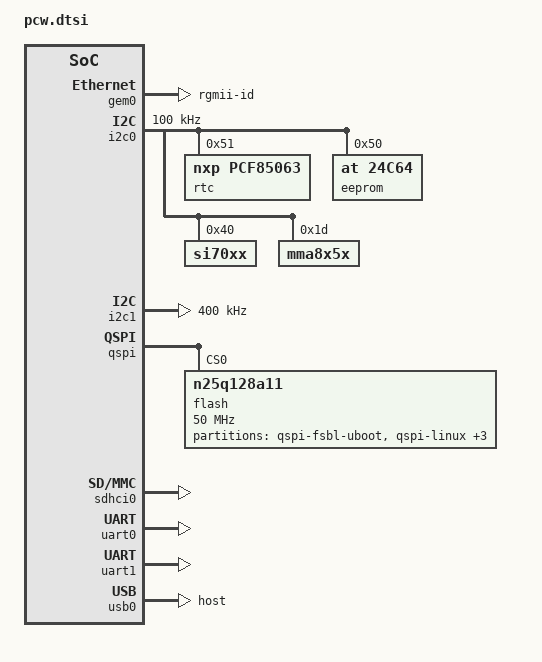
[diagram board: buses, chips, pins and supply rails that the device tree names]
/*
 * CAUTION: This file is automatically generated by Xilinx.
 * Version:  
 * Today is: Mon Aug 21 14:07:54 2017
*/


/ {
	cpus {
		cpu@0 {
			operating-points = <800000 1000000 400000 1000000 200000 1000000>;
		};
	};
};

&gem0 {
	enet-reset = <&gpio0 51 0>;
	phy-mode = "rgmii-id";
	status = "okay";
	xlnx,ptp-enet-clock = <0x7f28150>;
};

&gpio0 {
	emio-gpio-width = <64>;
	gpio-mask-high = <0x0>;
	gpio-mask-low = <0x5600>;
};

&i2c0 {
	status = "okay";
	clock-frequency = <100000>;
	
	rtc@51 {
                compatible = "nxp,pcf85063";
                reg = <0x51>;
        };
	
	eeprom@50 {
                compatible = "at,24c64";
                reg = <0x50>;
        };
	
	si70xx: si70xx@40 {
                compatible = "si70xx";
                reg = <0x40>;
        };
	
	mma8x5x: mma8x5x@1d {
                compatible = "mma8x5x";
                reg = <0x1d>;		
        };
};

&i2c1 {
	clock-frequency = <400000>;
	status = "okay";
};

&intc {
	num_cpus = <2>;
	num_interrupts = <96>;
};

&qspi {
	is-dual = <0>;
	num-cs = <1>;
	status = "okay";
	#address-cells = <1>;
	#size-cells = <0>;
	flash@0 {
              compatible = "n25q128a11";
              reg = <0x0>;
              spi-tx-bus-width = <1>;
              spi-rx-bus-width = <4>;
              spi-max-frequency = <50000000>;
              #address-cells = <1>;
              #size-cells = <1>;
              partition@qspi-fsbl-uboot {
                        label = "qspi-fsbl-uboot";
                        reg = <0x0 0x100000>;
              };
              partition@qspi-linux {
                        label = "qspi-linux";
                        reg = <0x100000 0x500000>;
              };
              partition@qspi-device-tree {
                        label = "qspi-device-tree";
                        reg = <0x600000 0x20000>;
              };
              partition@qspi-rootfs {
                        label = "qspi-rootfs";
                        reg = <0x620000 0x5E0000>;
              };
              partition@qspi-bitstream {
                        label = "qspi-bitstream";
                        reg = <0xC00000 0x400000>;
              };
      };
};

&sdhci0 {
	status = "okay";
	xlnx,has-cd = <0x1>;
	xlnx,has-power = <0x0>;
	xlnx,has-wp = <0x0>;
};

&uart0 {
	device_type = "serial";
	port-number = <0>;
	status = "okay";
};

&uart1 {
	device_type = "serial";
	port-number = <1>;
	status = "okay";
};

&usb0 {
	dr_mode = "host";
	phy_type = "ulpi";
	status = "okay";
	usb-reset = <&gpio0 9 0>;
};

&clkc {
	fclk-enable = <0xf>;
	ps-clk-frequency = <50000000>;
};
